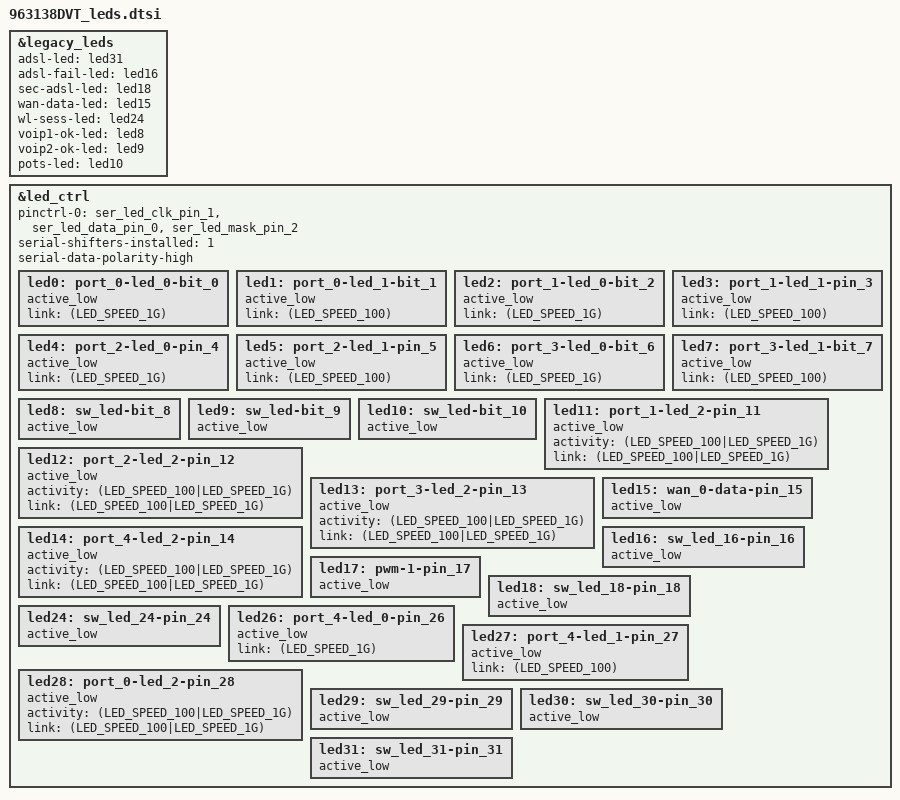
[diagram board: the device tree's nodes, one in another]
/* 963138DVT board led definition */

&legacy_leds {
	adsl-led = <&led31>;
	adsl-fail-led = <&led16>;
	sec-adsl-led = <&led18>;
	wan-data-led = <&led15>;
	wl-sess-led = <&led24>;
	voip1-ok-led = <&led8>;
	voip2-ok-led = <&led9>;
	pots-led =  <&led10>;
};

&led_ctrl {
    pinctrl-names = "default";
    pinctrl-0 = <&ser_led_clk_pin_1 &ser_led_data_pin_0 &ser_led_mask_pin_2>;
    serial-shifters-installed = <1>;
    serial-data-polarity-high;

    led0: port_0-led_0-bit_0 {
        active_low;
        link = <(LED_SPEED_1G)>;
        status = "okay";
    };
    led1: port_0-led_1-bit_1 {
        active_low;
        link = <(LED_SPEED_100)>;
        status = "okay";
    };
    led2: port_1-led_0-bit_2 {
        active_low;
        link = <(LED_SPEED_1G)>;
        status = "okay";
    };
    led3: port_1-led_1-pin_3 {
        active_low;
        link = <(LED_SPEED_100)>;
        status = "okay";
    };
    led4: port_2-led_0-pin_4 {
        active_low;
        link = <(LED_SPEED_1G)>;
        status = "okay";
    };
    led5: port_2-led_1-pin_5 {
        active_low;
        link = <(LED_SPEED_100)>;
        status = "okay";
    };
    led6: port_3-led_0-bit_6 {
        active_low;
        link = <(LED_SPEED_1G)>;
        status = "okay";
    };
    led7: port_3-led_1-bit_7 {
        active_low;
        link = <(LED_SPEED_100)>;
        status = "okay";
    };
	led8: sw_led-bit_8 {
        active_low;
        status = "okay";
    };
	led9: sw_led-bit_9 {
        active_low;
        status = "okay";
    };
	led10: sw_led-bit_10 {
        active_low;
        status = "okay";
    };
    led11: port_1-led_2-pin_11 {
        active_low;
        activity = <(LED_SPEED_100|LED_SPEED_1G)>;
        link = <(LED_SPEED_100|LED_SPEED_1G)>;
        status = "okay";
    };
    led12: port_2-led_2-pin_12 {
        active_low;
        activity = <(LED_SPEED_100|LED_SPEED_1G)>;
        link = <(LED_SPEED_100|LED_SPEED_1G)>;
        status = "okay";
    };
    led13: port_3-led_2-pin_13 {
        active_low;
        activity = <(LED_SPEED_100|LED_SPEED_1G)>;
        link = <(LED_SPEED_100|LED_SPEED_1G)>;		
        status = "okay";
    };
    led14: port_4-led_2-pin_14 {
        active_low;
        activity = <(LED_SPEED_100|LED_SPEED_1G)>;
        link = <(LED_SPEED_100|LED_SPEED_1G)>;
        status = "okay";
    };
    led15: wan_0-data-pin_15 {
        active_low;
        status = "okay";
    };
    led16: sw_led_16-pin_16 {
        active_low;
        status = "okay";
    };
    led17: pwm-1-pin_17 {
        active_low;
        status = "okay";
    };
    led18: sw_led_18-pin_18 {
        active_low;
        status = "okay";
    };
    led24: sw_led_24-pin_24 {
        active_low;
        status = "okay";
    };
    led26: port_4-led_0-pin_26 {
        active_low;
        link = <(LED_SPEED_1G)>;
        status = "okay";
    };
    led27: port_4-led_1-pin_27 {
        active_low;
        link = <(LED_SPEED_100)>;
        status = "okay";
    };	
    led28: port_0-led_2-pin_28 {
        active_low;
        activity = <(LED_SPEED_100|LED_SPEED_1G)>;
        link = <(LED_SPEED_100|LED_SPEED_1G)>;
        status = "okay";
    };
    led29: sw_led_29-pin_29 {
        active_low;
        status = "okay";
    };
    led30: sw_led_30-pin_30 {
        active_low;
        status = "okay";
    };
    led31: sw_led_31-pin_31 {
        active_low;
        status = "okay";
    };	
};
